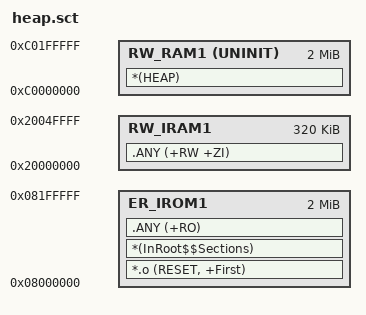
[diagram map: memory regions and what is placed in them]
LR_IROM1 0x08000000 0x00200000  {    ; load region size_region
  ER_IROM1 0x08000000 0x00200000  {  ; load address = execution address
   *.o (RESET, +First)
   *(InRoot$$Sections)
   .ANY (+RO)
  }
  RW_IRAM1 0x20000000 0x00050000  {  ; Internal SRAM
   .ANY (+RW +ZI)
  }
  RW_RAM1 0xC0000000 UNINIT 0x00200000  { ; External SDRAM
   *(HEAP)
  }
}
